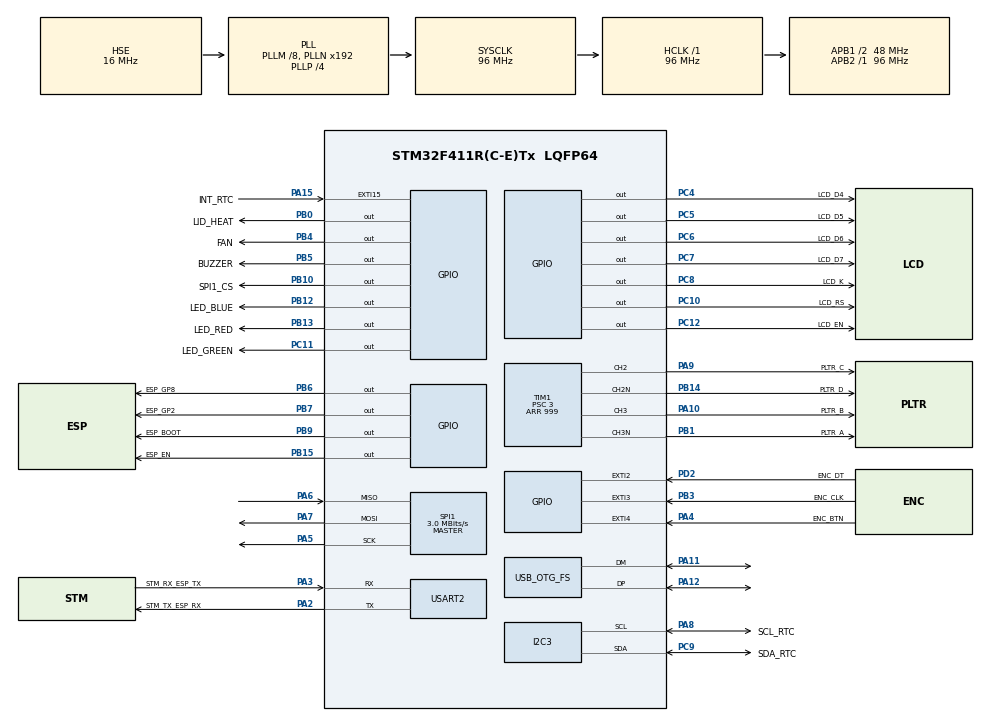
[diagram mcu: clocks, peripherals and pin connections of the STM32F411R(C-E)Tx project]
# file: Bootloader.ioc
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Dma.Request0=USART2_RX
Dma.USART2_RX.0.Direction=DMA_PERIPH_TO_MEMORY
Dma.USART2_RX.0.FIFOMode=DMA_FIFOMODE_DISABLE
Dma.USART2_RX.0.Instance=DMA1_Stream7
Dma.USART2_RX.0.MemDataAlignment=DMA_MDATAALIGN_BYTE
Dma.USART2_RX.0.MemInc=DMA_MINC_ENABLE
Dma.USART2_RX.0.Mode=DMA_CIRCULAR
Dma.USART2_RX.0.PeriphDataAlignment=DMA_PDATAALIGN_BYTE
Dma.USART2_RX.0.PeriphInc=DMA_PINC_DISABLE
Dma.USART2_RX.0.Priority=DMA_PRIORITY_LOW
Mcu.Family=STM32F4
Mcu.Name=STM32F411R(C-E)Tx
Mcu.Package=LQFP64
NVIC.DMA1_Stream7_IRQn=true\:0\:0\:false\:false\:true\:false\:true\:true
NVIC.EXTI2_IRQn=true\:0\:0\:false\:false\:true\:true\:true\:true
NVIC.EXTI3_IRQn=true\:0\:0\:false\:false\:true\:true\:true\:true
NVIC.EXTI4_IRQn=true\:12\:0\:true\:false\:true\:true\:true\:true
NVIC.OTG_FS_IRQn=true\:1\:0\:true\:false\:true\:false\:true\:true
NVIC.PriorityGroup=NVIC_PRIORITYGROUP_4
NVIC.TIM1_BRK_TIM9_IRQn=true\:0\:0\:false\:false\:true\:true\:true\:true
NVIC.TIM1_TRG_COM_TIM11_IRQn=true\:0\:0\:false\:false\:true\:false\:true\:true
NVIC.TIM1_UP_TIM10_IRQn=true\:0\:0\:true\:false\:true\:false\:true\:true
NVIC.TIM4_IRQn=true\:0\:0\:false\:false\:true\:true\:true\:true
NVIC.TimeBase=TIM1_UP_TIM10_IRQn
NVIC.TimeBaseIP=TIM10
NVIC.USART2_IRQn=true\:0\:0\:true\:false\:true\:true\:true\:true
PA10.GPIO_Label=PLTR_B
PA10.Signal=S_TIM1_CH3
PA11.Mode=Device_Only
PA11.Signal=USB_OTG_FS_DM
PA12.Mode=Device_Only
PA12.Signal=USB_OTG_FS_DP
PA13.Mode=Serial_Wire
PA13.Signal=SYS_JTMS-SWDIO
PA14.Mode=Serial_Wire
PA14.Signal=SYS_JTCK-SWCLK
PA15.GPIO_Label=INT_RTC
PA15.GPIO_ModeDefaultEXTI=GPIO_MODE_IT_FALLING
PA15.GPIO_PuPd=GPIO_PULLUP
PA15.Signal=GPXTI15
PA2.GPIO_Label=STM_TX_ESP_RX
PA2.Mode=Asynchronous
PA2.Signal=USART2_TX
PA3.GPIO_Label=STM_RX_ESP_TX
PA3.Mode=Asynchronous
PA3.Signal=USART2_RX
PA4.GPIO_Label=ENC_BTN
PA4.Signal=GPXTI4
PA5.Mode=Full_Duplex_Master
PA5.Signal=SPI1_SCK
PA6.Mode=Full_Duplex_Master
PA6.Signal=SPI1_MISO
PA7.Mode=Full_Duplex_Master
PA7.Signal=SPI1_MOSI
PA8.GPIO_Label=SCL_RTC
PA8.GPIO_Pu=GPIO_PULLUP
PA8.Mode=I2C
PA8.Signal=I2C3_SCL
PA9.GPIO_Label=PLTR_C
PA9.Signal=S_TIM1_CH2
PB0.GPIO_Label=LID_HEAT
PB0.Signal=GPIO_Output
PB1.GPIO_Label=PLTR_A
PB1.Mode=PWM Generation3 CH3 CH3N
PB1.Signal=TIM1_CH3N
PB10.GPIO_Label=SPI1_CS
PB10.Signal=GPIO_Output
PB12.GPIO_Label=LED_BLUE
PB12.Signal=GPIO_Output
PB13.GPIO_Label=LED_RED
PB13.Signal=GPIO_Output
PB14.GPIO_Label=PLTR_D
PB14.Mode=PWM Generation2 CH2 CH2N
PB14.Signal=TIM1_CH2N
PB15.GPIO_Label=ESP_EN
PB15.Signal=GPIO_Output
PB3.GPIO_Label=ENC_CLK
PB3.GPIO_ModeDefaultEXTI=GPIO_MODE_IT_RISING_FALLING
PB3.GPIO_PuPd=GPIO_PULLUP
PB3.Signal=GPXTI3
PB4.GPIO_Label=FAN
PB4.Signal=GPIO_Output
PB5.GPIO_Label=BUZZER
PB5.Signal=GPIO_Output
PB6.GPIO_Label=ESP_GP8
PB6.Signal=GPIO_Output
PB7.GPIO_Label=ESP_GP2
PB7.Signal=GPIO_Output
PB9.GPIO_Label=ESP_BOOT
PB9.Signal=GPIO_Output
PC10.GPIO_Label=LCD_RS
PC10.Signal=GPIO_Output
PC11.GPIO_Label=LED_GREEN
PC11.Signal=GPIO_Output
PC12.GPIO_Label=LCD_EN
PC12.Signal=GPIO_Output
PC14-OSC32_IN.Mode=LSE-External-Oscillator
PC14-OSC32_IN.Signal=RCC_OSC32_IN
PC15-OSC32_OUT.Mode=LSE-External-Oscillator
PC15-OSC32_OUT.Signal=RCC_OSC32_OUT
PC4.GPIO_Label=LCD_D4
PC4.Signal=GPIO_Output
PC5.GPIO_Label=LCD_D5
PC5.Signal=GPIO_Output
PC6.GPIO_Label=LCD_D6
PC6.Signal=GPIO_Output
PC7.GPIO_Label=LCD_D7
PC7.Signal=GPIO_Output
PC8.GPIO_Label=LCD_K
PC8.Signal=GPIO_Output
PC9.GPIO_Label=SDA_RTC
PC9.GPIO_Pu=GPIO_PULLUP
PC9.Mode=I2C
PC9.Signal=I2C3_SDA
PD2.GPIO_Label=ENC_DT
PD2.GPIO_ModeDefaultEXTI=GPIO_MODE_IT_RISING_FALLING
PD2.GPIO_PuPd=GPIO_PULLUP
PD2.Signal=GPXTI2
PH0\ -\ OSC_IN.Mode=HSE-External-Oscillator
PH0\ -\ OSC_IN.Signal=RCC_OSC_IN
PH1\ -\ OSC_OUT.Mode=HSE-External-Oscillator
PH1\ -\ OSC_OUT.Signal=RCC_OSC_OUT
ProjectManager.HeapSize=0x2000
ProjectManager.StackSize=0x1600
ProjectManager.TargetToolchain=STM32CubeIDE
RCC.48MHZClocksFreq_Value=48000000
RCC.AHBFreq_Value=96000000
RCC.APB1CLKDivider=RCC_HCLK_DIV2
RCC.APB1Freq_Value=48000000
RCC.APB1TimFreq_Value=96000000
RCC.APB2Freq_Value=96000000
RCC.APB2TimFreq_Value=96000000
RCC.CortexFreq_Value=96000000
RCC.EnbaleCSS=true
RCC.HCLKFreq_Value=96000000
RCC.HSE_VALUE=16000000
RCC.HSI_VALUE=16000000
RCC.PLLM=8
RCC.PLLP=RCC_PLLP_DIV4
RCC.PLLQ=8
RCC.SYSCLKFreq_VALUE=96000000
RCC.SYSCLKSource=RCC_SYSCLKSOURCE_PLLCLK
RCC.VCOOutputFreq_Value=384000000
SH.S_TIM1_CH2.0=TIM1_CH2,PWM Generation2 CH2 CH2N
SH.S_TIM1_CH3.0=TIM1_CH3,PWM Generation3 CH3 CH3N
SPI1.BaudRatePrescaler=SPI_BAUDRATEPRESCALER_32
SPI1.CalculateBaudRate=3.0 MBits/s
SPI1.Direction=SPI_DIRECTION_2LINES
SPI1.Mode=SPI_MODE_MASTER
SPI1.VirtualType=VM_MASTER
TIM1.BreakPolarity=TIM_BREAKPOLARITY_HIGH
TIM1.Channel-PWM\ Generation2\ CH2\ CH2N=TIM_CHANNEL_2
TIM1.Channel-PWM\ Generation3\ CH3\ CH3N=TIM_CHANNEL_3
TIM1.DeadTime=50
TIM1.OCFastMode_PWM-PWM\ Generation2\ CH2\ CH2N=TIM_OCFAST_DISABLE
TIM1.OCIdleState_2=TIM_OCIDLESTATE_RESET
TIM1.OCMode_PWM-PWM\ Generation2\ CH2\ CH2N=TIM_OCMODE_PWM1
TIM1.OCNPolarity_2=TIM_OCNPOLARITY_HIGH
TIM1.Period=999
TIM1.Prescaler=3
TIM1.Pulse-PWM\ Generation2\ CH2\ CH2N=0
TIM4.Period=99
TIM4.Prescaler=9999
TIM9.Period=9999
TIM9.Prescaler=9999
USART2.VirtualMode=VM_ASYNC
USB_DEVICE.CLASS_NAME_FS=CDC
USB_DEVICE.PRODUCT_STRING_CDC_FS=molstem bootloader
USB_DEVICE.VirtualMode=Cdc
USB_DEVICE.VirtualModeFS=Cdc_FS
USB_OTG_FS.VirtualMode=Device_Only
VP_MBEDTLS_VS_MBEDTLS.Mode=Enabled
VP_SYS_VS_tim10.Mode=TIM10
VP_TIM1_VS_ClockSourceINT.Mode=Internal
VP_TIM4_VS_ClockSourceINT.Mode=Internal
VP_TIM9_VS_ClockSourceINT.Mode=Internal
VP_USB_DEVICE_VS_USB_DEVICE_CDC_FS.Mode=CDC_FS
board=custom

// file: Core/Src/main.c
/* USER CODE BEGIN Header */
/**
 ******************************************************************************
 * @file           : main.c
 * @brief          : Main program body
 ******************************************************************************
 * @attention
 *
 * Copyright (c) 2025 STMicroelectronics.
 * All rights reserved.
 *
 * This software is licensed under terms that can be found in the LICENSE file
 * in the root directory of this software component.
 * If no LICENSE file comes with this software, it is provided AS-IS.
 *
 ******************************************************************************
 */
/* USER CODE END Header */
#include "main.h"
#include "dma.h"
#include "i2c.h"
#include "mbedtls.h"
#include "spi.h"
#include "tim.h"
#include "usart.h"
#include "usb_device.h"
#include "gpio.h"

void SystemClock_Config(void);

int main(void)
{

  /* MCU Configuration--------------------------------------------------------*/

  /* Reset of all peripherals, Initializes the Flash interface and the Systick. */
  HAL_Init();

  /* Configure the system clock */
  SystemClock_Config();

  /* Initialize all configured peripherals */
  MX_GPIO_Init();
  MX_DMA_Init();
  MX_TIM1_Init();
  MX_SPI1_Init();
  MX_TIM9_Init();
  MX_I2C3_Init();
  MX_TIM4_Init();
  MX_USB_DEVICE_Init();
  MX_MBEDTLS_Init();
  MX_USART2_UART_Init();
  /* USER CODE BEGIN 2 */
  extern int molstem_before_kernel_start();
  if (!molstem_before_kernel_start()) {
    for(;;) {
	}
  }
  /* USER CODE END 2 */

  /* Infinite loop */
	while (1)
	{

	}
}

void SystemClock_Config(void)
{
  RCC_OscInitTypeDef RCC_OscInitStruct = {0};
  RCC_ClkInitTypeDef RCC_ClkInitStruct = {0};

  /** Configure the main internal regulator output voltage
  */
  __HAL_RCC_PWR_CLK_ENABLE();
  __HAL_PWR_VOLTAGESCALING_CONFIG(PWR_REGULATOR_VOLTAGE_SCALE1);

  /** Initializes the RCC Oscillators according to the specified parameters
  * in the RCC_OscInitTypeDef structure.
  */
  RCC_OscInitStruct.OscillatorType = RCC_OSCILLATORTYPE_HSE;
  RCC_OscInitStruct.HSEState = RCC_HSE_ON;
  RCC_OscInitStruct.PLL.PLLState = RCC_PLL_ON;
  RCC_OscInitStruct.PLL.PLLSource = RCC_PLLSOURCE_HSE;
  RCC_OscInitStruct.PLL.PLLM = 8;
  RCC_OscInitStruct.PLL.PLLN = 192;
  RCC_OscInitStruct.PLL.PLLP = RCC_PLLP_DIV4;
  RCC_OscInitStruct.PLL.PLLQ = 8;
  if (HAL_RCC_OscConfig(&RCC_OscInitStruct) != HAL_OK)
  {
    Error_Handler();
  }

  /** Initializes the CPU, AHB and APB buses clocks
  */
  RCC_ClkInitStruct.ClockType = RCC_CLOCKTYPE_HCLK|RCC_CLOCKTYPE_SYSCLK
                              |RCC_CLOCKTYPE_PCLK1|RCC_CLOCKTYPE_PCLK2;
  RCC_ClkInitStruct.SYSCLKSource = RCC_SYSCLKSOURCE_PLLCLK;
  RCC_ClkInitStruct.AHBCLKDivider = RCC_SYSCLK_DIV1;
  RCC_ClkInitStruct.APB1CLKDivider = RCC_HCLK_DIV2;
  RCC_ClkInitStruct.APB2CLKDivider = RCC_HCLK_DIV1;

  if (HAL_RCC_ClockConfig(&RCC_ClkInitStruct, FLASH_LATENCY_3) != HAL_OK)
  {
    Error_Handler();
  }

  /** Enables the Clock Security System
  */
  HAL_RCC_EnableCSS();
}

void HAL_TIM_PeriodElapsedCallback(TIM_HandleTypeDef *htim)
{
  if (htim->Instance == TIM10)
  {
    HAL_IncTick();
  }
}

void Error_Handler(void)
{
	__disable_irq();
	while (1)
	{
	}
}
